# RN831X_RN861X_MCU register map
File version: v0.0.1
CPU: RN831X_RN861X_MCU r1p0, little endian, MPU, no FPU
Registers are 32-bit, read-write, reset 0x0 unless marked. A register's access mark holds for its fields unless they carry their own. Offsets are from the block's base; [hi:lo] are bit positions; {n}, {i} and the like mark numbered series; 'fields as' and 'values as' point back to an identical list.

## GIC_CORE0 — GIC Module core0
Base 0x3001C000
Same registers: GIC_CORE1 0xB001C000
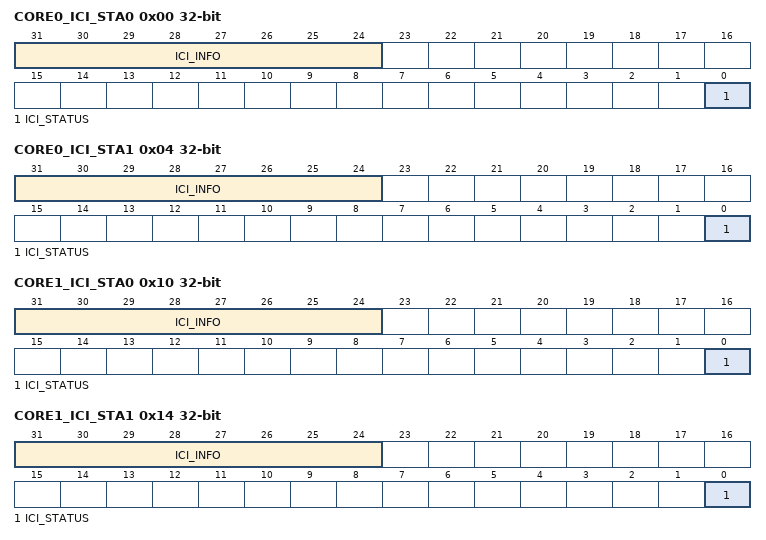
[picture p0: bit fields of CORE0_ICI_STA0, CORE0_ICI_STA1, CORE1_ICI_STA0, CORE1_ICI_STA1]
0x00 CORE0_ICI_STA0 access per field — CORE0 Inter-Core Interrupt Status Register 0
  [31:24] ICI_INFO ro — 8-bit message received by CORE0 when receiving inter-core interrupt from CORE0
  [0] ICI_STATUS rw write-1-clears — Inter-core interrupt status bit sent from CORE0 to CORE0
0x04 CORE0_ICI_STA1 access per field — CORE0 Inter-Core Interrupt Status Register 1
  [31:24] ICI_INFO ro — 8-bit message received by CORE0 when receiving inter-core interrupt from CORE1
  [0] ICI_STATUS rw write-1-clears — Inter-core interrupt status bit sent from CORE1 to CORE0
0x10 CORE1_ICI_STA0 access per field — CORE1 Inter-Core Interrupt Status Register 0
  [31:24] ICI_INFO ro — 8-bit message received by CORE0 when receiving inter-core interrupt from CORE1
  [0] ICI_STATUS rw write-1-clears — Inter-core interrupt status bit sent from CORE0 to CORE0
0x14 CORE1_ICI_STA1 access per field — CORE1 Inter-Core Interrupt Status Register 1
  fields as CORE0_ICI_STA0
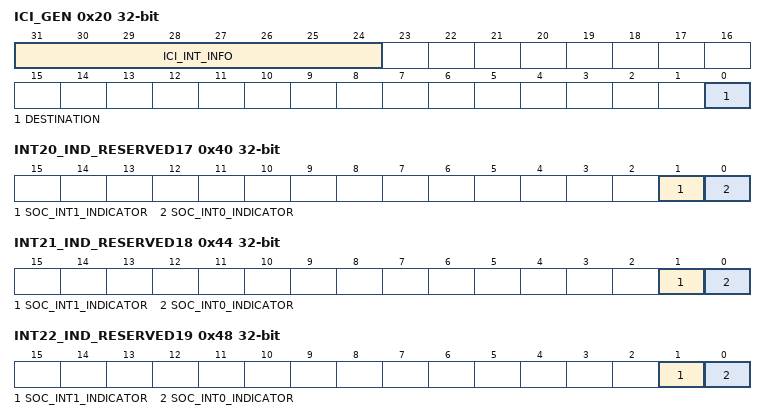
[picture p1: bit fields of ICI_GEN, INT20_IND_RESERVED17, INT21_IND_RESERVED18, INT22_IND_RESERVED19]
0x20 ICI_GEN wo — Inter-Core Interrupt Control Register
  [31:24] ICI_INT_INFO — 8-bit message sent to the core receiving inter-core interrupt
  [0] DESTINATION — Write the CORE_id of the core that will receive the inter-core interrupt
0x24 CORE_IND_LOCK access not given — Core Interrupt Lock Register
  [31:0] CORE_IND_LOCK — Core interrupt lock configuration
0x28 CORE_NUM access not given — Core Number Register
  [31:0] CORE_NUM — Number of cores in the system
0x2C HART_NUM access not given — HART Number Register
  [31:0] HART_NUM — Number of HART buses in the system
0x30 SOC_IRQ_NUM access not given — Interrupt Number Register
  [31:0] SOC_IRQ_NUM — Number of external interrupts in the system
0x40 INT20_IND_RESERVED17 — SOC Interrupt20 Indicator Register
  [1] SOC_INT1_INDICATOR — Whether external interrupt n is assigned to CORE1
  [0] SOC_INT0_INDICATOR — Whether external interrupt n is assigned to CORE0
0x44 INT21_IND_RESERVED18 — SOC Interrupt21 Indicator Register
  fields as INT20_IND_RESERVED17
0x48 INT22_IND_RESERVED19 — SOC Interrupt22 Indicator Register
  fields as INT20_IND_RESERVED17
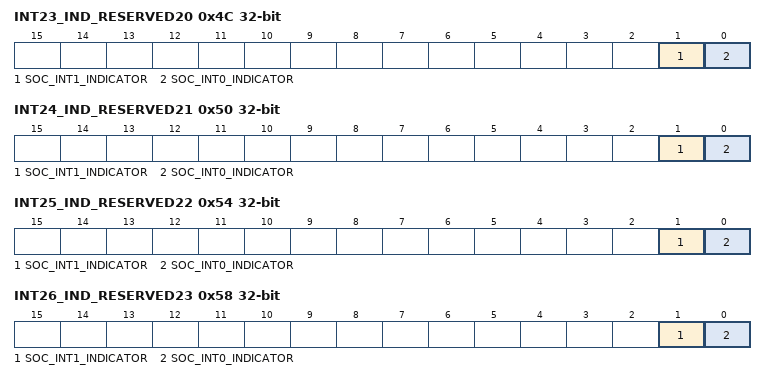
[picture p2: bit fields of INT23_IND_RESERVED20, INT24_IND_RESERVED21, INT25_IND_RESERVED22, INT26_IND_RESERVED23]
0x4C INT23_IND_RESERVED20 — SOC Interrupt23 Indicator Register
  fields as INT20_IND_RESERVED17
0x50 INT24_IND_RESERVED21 — SOC Interrupt24 Indicator Register
  fields as INT20_IND_RESERVED17
0x54 INT25_IND_RESERVED22 — SOC Interrupt25 Indicator Register
  fields as INT20_IND_RESERVED17
0x58 INT26_IND_RESERVED23 — SOC Interrupt26 Indicator Register
  fields as INT20_IND_RESERVED17
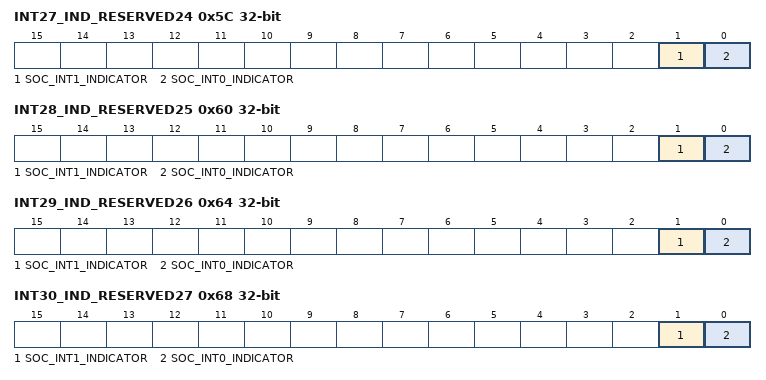
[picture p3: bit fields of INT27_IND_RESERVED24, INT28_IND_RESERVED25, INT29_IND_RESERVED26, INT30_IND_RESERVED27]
0x5C INT27_IND_RESERVED24 — SOC Interrupt27 Indicator Register
  fields as INT20_IND_RESERVED17
0x60 INT28_IND_RESERVED25 — SOC Interrupt28 Indicator Register
  fields as INT20_IND_RESERVED17
0x64 INT29_IND_RESERVED26 — SOC Interrupt29 Indicator Register
  fields as INT20_IND_RESERVED17
0x68 INT30_IND_RESERVED27 — SOC Interrupt30 Indicator Register
  fields as INT20_IND_RESERVED17
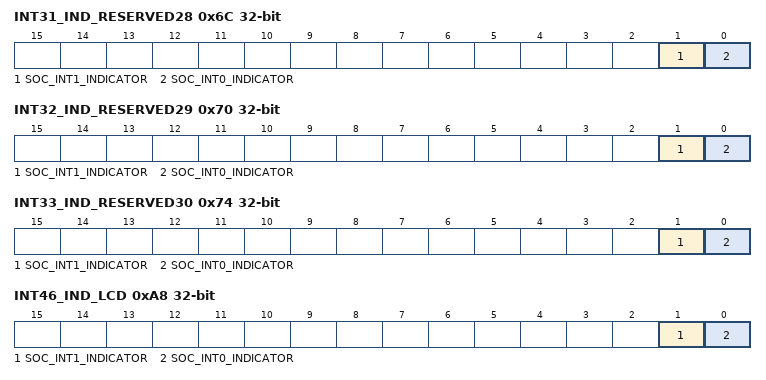
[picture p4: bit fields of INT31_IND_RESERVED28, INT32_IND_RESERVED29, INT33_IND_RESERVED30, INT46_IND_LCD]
0x6C INT31_IND_RESERVED28 — SOC Interrupt31 Indicator Register
  fields as INT20_IND_RESERVED17
0x70 INT32_IND_RESERVED29 — SOC Interrupt32 Indicator Register
  fields as INT20_IND_RESERVED17
0x74 INT33_IND_RESERVED30 — SOC Interrupt33 Indicator Register
  fields as INT20_IND_RESERVED17
0x78 INT34_IND_RESERVED31 access not given — SOC Interrupt34 Indicator Register
  [0] SOC_INT_INDICATOR — Whether external interrupt n is assigned to CORE0/CORE1
0x7C INT35_IND_RESERVED32 access not given — SOC Interrupt35 Indicator Register
  fields as INT34_IND_RESERVED31
0x80 INT36_IND_RESERVED33 access not given — SOC Interrupt36 Indicator Register
  fields as INT34_IND_RESERVED31
0x84 INT37_IND_RESERVED34 access not given — SOC Interrupt37 Indicator Register
  fields as INT34_IND_RESERVED31
0x88 INT38_IND_RESERVED35 access not given — SOC Interrupt38 Indicator Register
  fields as INT34_IND_RESERVED31
0x8C INT39_IND_RESERVED36 access not given — SOC Interrupt39 Indicator Register
  fields as INT34_IND_RESERVED31
0x90 INT40_IND_RESERVED37 access not given — SOC Interrupt40 Indicator Register
  fields as INT34_IND_RESERVED31
0x94 INT41_IND_RESERVED38 access not given — SOC Interrupt41 Indicator Register
  fields as INT34_IND_RESERVED31
0x98 INT42_IND_RESERVED39 access not given — SOC Interrupt42 Indicator Register
  fields as INT34_IND_RESERVED31
0x9C INT43_IND_RESERVED40 access not given — SOC Interrupt43 Indicator Register
  fields as INT34_IND_RESERVED31
0xA0 INT44_IND_RESERVED41 access not given — SOC Interrupt44 Indicator Register
  fields as INT34_IND_RESERVED31
0xA4 INT45_IND_RESERVED42 access not given — SOC Interrupt45 Indicator Register
  fields as INT34_IND_RESERVED31
0xA8 INT46_IND_LCD — SOC Interrupt46 Indicator Register
  fields as INT20_IND_RESERVED17
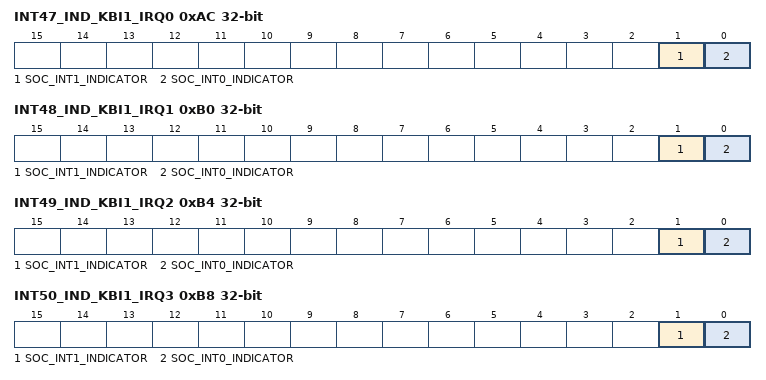
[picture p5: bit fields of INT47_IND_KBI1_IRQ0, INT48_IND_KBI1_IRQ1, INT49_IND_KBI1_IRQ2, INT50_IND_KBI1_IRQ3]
0xAC INT47_IND_KBI1_IRQ0 — SOC Interrupt47 Indicator Register
  fields as INT20_IND_RESERVED17
0xB0 INT48_IND_KBI1_IRQ1 — SOC Interrupt48 Indicator Register
  fields as INT20_IND_RESERVED17
0xB4 INT49_IND_KBI1_IRQ2 — SOC Interrupt49 Indicator Register
  fields as INT20_IND_RESERVED17
0xB8 INT50_IND_KBI1_IRQ3 — SOC Interrupt50 Indicator Register
  fields as INT20_IND_RESERVED17
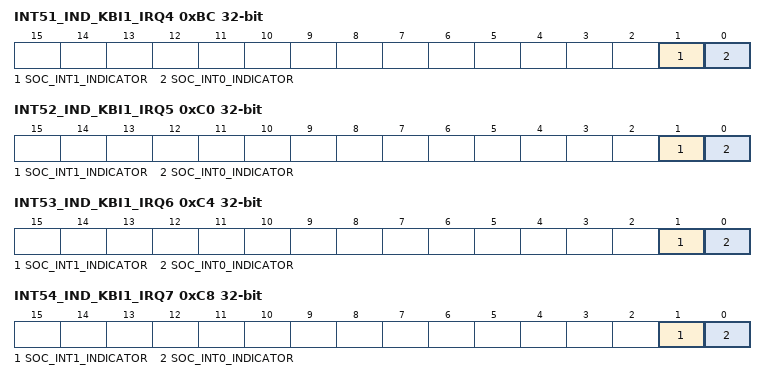
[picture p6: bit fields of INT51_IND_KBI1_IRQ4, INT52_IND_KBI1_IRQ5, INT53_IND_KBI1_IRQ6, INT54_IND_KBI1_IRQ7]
0xBC INT51_IND_KBI1_IRQ4 — SOC Interrupt51 Indicator Register
  fields as INT20_IND_RESERVED17
0xC0 INT52_IND_KBI1_IRQ5 — SOC Interrupt52 Indicator Register
  fields as INT20_IND_RESERVED17
0xC4 INT53_IND_KBI1_IRQ6 — SOC Interrupt53 Indicator Register
  fields as INT20_IND_RESERVED17
0xC8 INT54_IND_KBI1_IRQ7 — SOC Interrupt54 Indicator Register
  fields as INT20_IND_RESERVED17
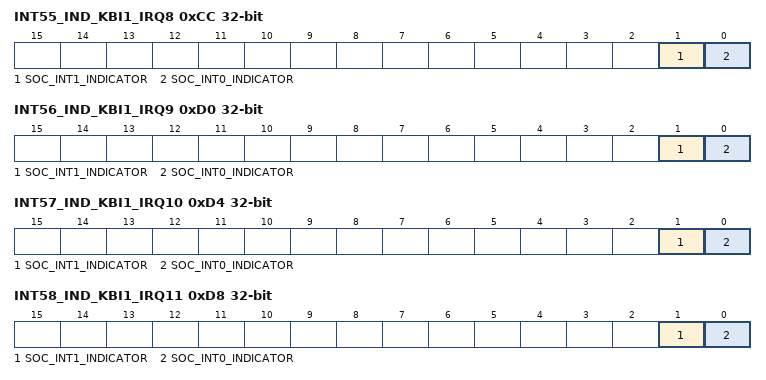
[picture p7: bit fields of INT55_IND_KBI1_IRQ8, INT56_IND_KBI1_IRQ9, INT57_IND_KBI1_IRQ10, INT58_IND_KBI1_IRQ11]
0xCC INT55_IND_KBI1_IRQ8 — SOC Interrupt55 Indicator Register
  fields as INT20_IND_RESERVED17
0xD0 INT56_IND_KBI1_IRQ9 — SOC Interrupt56 Indicator Register
  fields as INT20_IND_RESERVED17
0xD4 INT57_IND_KBI1_IRQ10 — SOC Interrupt57 Indicator Register
  fields as INT20_IND_RESERVED17
0xD8 INT58_IND_KBI1_IRQ11 — SOC Interrupt58 Indicator Register
  fields as INT20_IND_RESERVED17
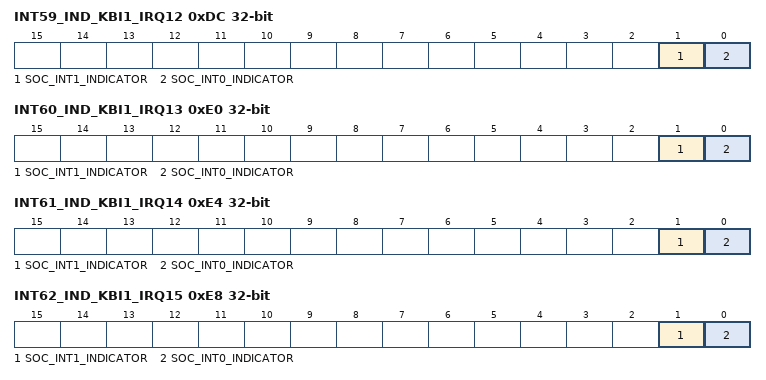
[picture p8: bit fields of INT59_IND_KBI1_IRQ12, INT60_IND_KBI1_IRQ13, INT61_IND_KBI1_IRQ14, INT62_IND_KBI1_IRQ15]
0xDC INT59_IND_KBI1_IRQ12 — SOC Interrupt59 Indicator Register
  fields as INT20_IND_RESERVED17
0xE0 INT60_IND_KBI1_IRQ13 — SOC Interrupt60 Indicator Register
  fields as INT20_IND_RESERVED17
0xE4 INT61_IND_KBI1_IRQ14 — SOC Interrupt61 Indicator Register
  fields as INT20_IND_RESERVED17
0xE8 INT62_IND_KBI1_IRQ15 — SOC Interrupt62 Indicator Register
  fields as INT20_IND_RESERVED17
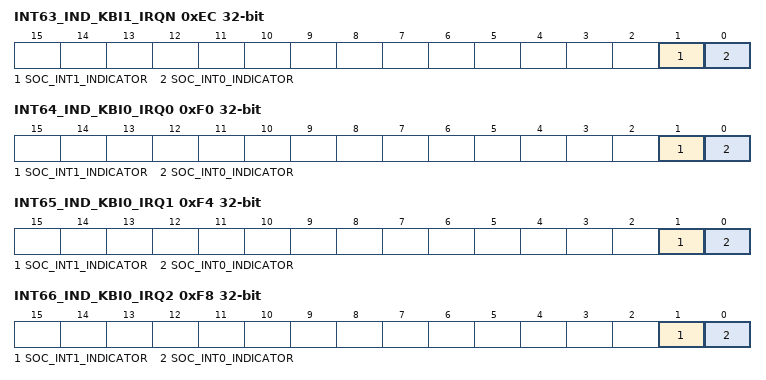
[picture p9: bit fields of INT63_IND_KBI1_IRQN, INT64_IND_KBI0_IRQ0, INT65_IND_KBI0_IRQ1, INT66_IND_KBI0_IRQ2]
0xEC INT63_IND_KBI1_IRQN — SOC Interrupt63 Indicator Register
  fields as INT20_IND_RESERVED17
0xF0 INT64_IND_KBI0_IRQ0 — SOC Interrupt64 Indicator Register
  fields as INT20_IND_RESERVED17
0xF4 INT65_IND_KBI0_IRQ1 — SOC Interrupt65 Indicator Register
  fields as INT20_IND_RESERVED17
0xF8 INT66_IND_KBI0_IRQ2 — SOC Interrupt66 Indicator Register
  fields as INT20_IND_RESERVED17
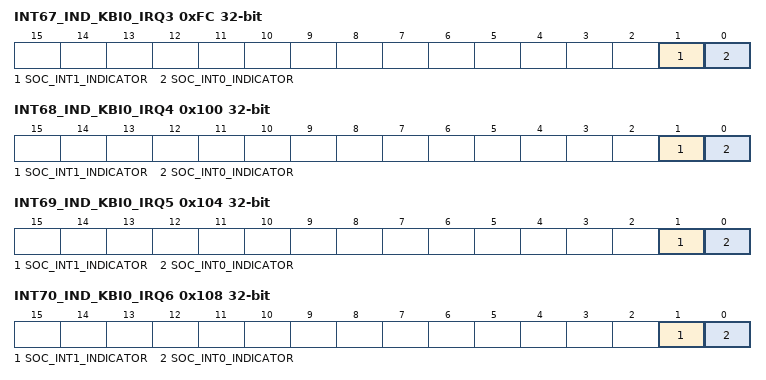
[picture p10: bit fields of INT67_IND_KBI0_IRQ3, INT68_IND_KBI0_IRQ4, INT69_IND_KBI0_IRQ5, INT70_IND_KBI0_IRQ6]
0xFC INT67_IND_KBI0_IRQ3 — SOC Interrupt67 Indicator Register
  fields as INT20_IND_RESERVED17
0x100 INT68_IND_KBI0_IRQ4 — SOC Interrupt68 Indicator Register
  fields as INT20_IND_RESERVED17
0x104 INT69_IND_KBI0_IRQ5 — SOC Interrupt69 Indicator Register
  fields as INT20_IND_RESERVED17
0x108 INT70_IND_KBI0_IRQ6 — SOC Interrupt70 Indicator Register
  fields as INT20_IND_RESERVED17
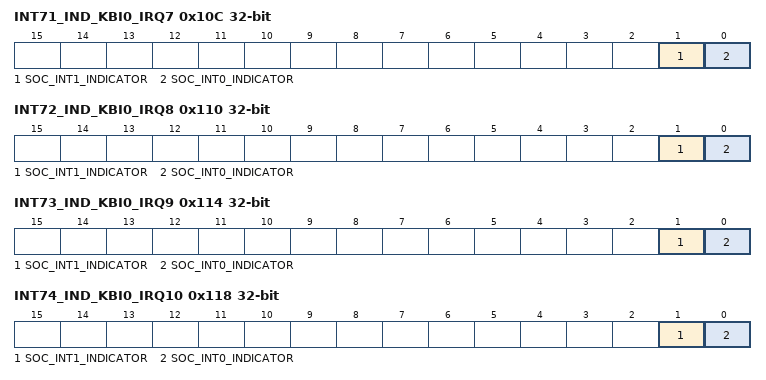
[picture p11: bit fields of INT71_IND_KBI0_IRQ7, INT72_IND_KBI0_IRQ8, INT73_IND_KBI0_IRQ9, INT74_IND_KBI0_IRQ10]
0x10C INT71_IND_KBI0_IRQ7 — SOC Interrupt71 Indicator Register
  fields as INT20_IND_RESERVED17
0x110 INT72_IND_KBI0_IRQ8 — SOC Interrupt72 Indicator Register
  fields as INT20_IND_RESERVED17
0x114 INT73_IND_KBI0_IRQ9 — SOC Interrupt73 Indicator Register
  fields as INT20_IND_RESERVED17
0x118 INT74_IND_KBI0_IRQ10 — SOC Interrupt74 Indicator Register
  fields as INT20_IND_RESERVED17
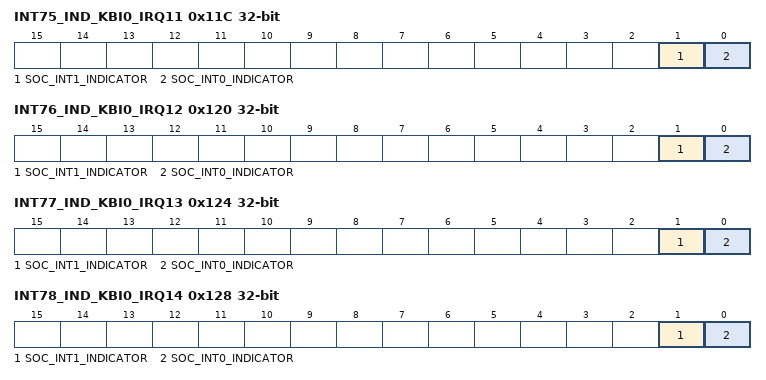
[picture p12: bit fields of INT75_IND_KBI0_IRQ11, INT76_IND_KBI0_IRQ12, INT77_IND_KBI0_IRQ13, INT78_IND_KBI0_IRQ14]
0x11C INT75_IND_KBI0_IRQ11 — SOC Interrupt75 Indicator Register
  fields as INT20_IND_RESERVED17
0x120 INT76_IND_KBI0_IRQ12 — SOC Interrupt76 Indicator Register
  fields as INT20_IND_RESERVED17
0x124 INT77_IND_KBI0_IRQ13 — SOC Interrupt77 Indicator Register
  fields as INT20_IND_RESERVED17
0x128 INT78_IND_KBI0_IRQ14 — SOC Interrupt78 Indicator Register
  fields as INT20_IND_RESERVED17
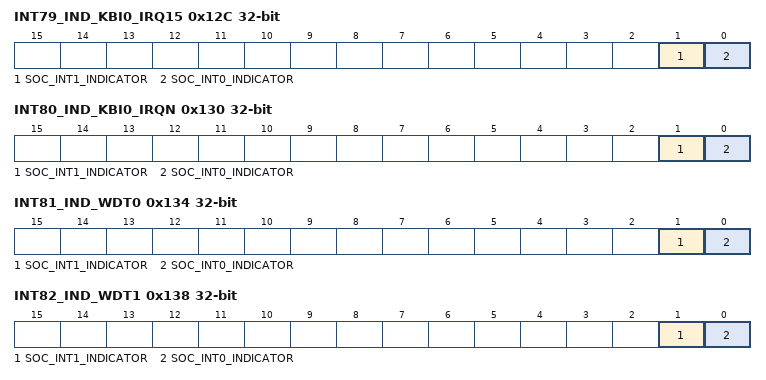
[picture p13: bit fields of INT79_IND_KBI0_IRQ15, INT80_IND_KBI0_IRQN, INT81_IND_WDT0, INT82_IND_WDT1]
0x12C INT79_IND_KBI0_IRQ15 — SOC Interrupt79 Indicator Register
  fields as INT20_IND_RESERVED17
0x130 INT80_IND_KBI0_IRQN — SOC Interrupt80 Indicator Register
  fields as INT20_IND_RESERVED17
0x134 INT81_IND_WDT0 — SOC Interrupt81 Indicator Register
  fields as INT20_IND_RESERVED17
0x138 INT82_IND_WDT1 — SOC Interrupt82 Indicator Register
  fields as INT20_IND_RESERVED17
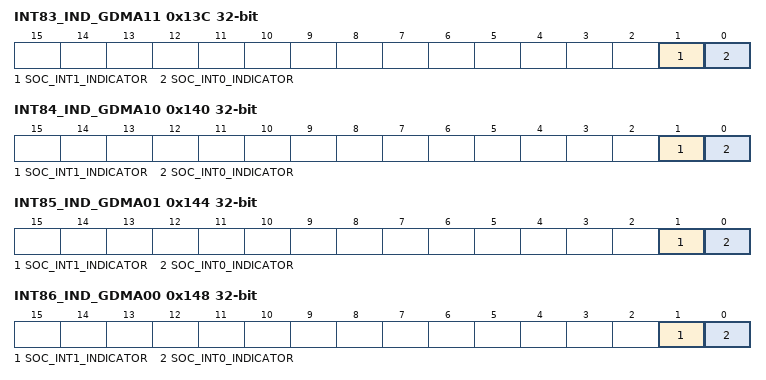
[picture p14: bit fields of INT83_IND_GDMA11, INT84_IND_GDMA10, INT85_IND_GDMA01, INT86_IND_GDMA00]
0x13C INT83_IND_GDMA11 — SOC Interrupt83 Indicator Register
  fields as INT20_IND_RESERVED17
0x140 INT84_IND_GDMA10 — SOC Interrupt84 Indicator Register
  fields as INT20_IND_RESERVED17
0x144 INT85_IND_GDMA01 — SOC Interrupt85 Indicator Register
  fields as INT20_IND_RESERVED17
0x148 INT86_IND_GDMA00 — SOC Interrupt86 Indicator Register
  fields as INT20_IND_RESERVED17
0x150 INT88_IND_SIMPTC0_0 — SOC Interrupt88 Indicator Register
  fields as INT20_IND_RESERVED17
0x154 INT89_IND_SIMPTC0_1 — SOC Interrupt89 Indicator Register
  fields as INT20_IND_RESERVED17
0x158 INT90_IND_SIMPTC0_2 — SOC Interrupt90 Indicator Register
  fields as INT20_IND_RESERVED17
0x15C INT91_IND_SIMPTC0_3 — SOC Interrupt91 Indicator Register
  fields as INT20_IND_RESERVED17
0x160 INT92_IND_SIMPTC1_0 — SOC Interrupt92 Indicator Register
  fields as INT20_IND_RESERVED17
0x164 INT93_IND_SIMPTC1_1 — SOC Interrupt93 Indicator Register
  fields as INT20_IND_RESERVED17
0x168 INT94_IND_SIMPTC1_2 — SOC Interrupt94 Indicator Register
  fields as INT20_IND_RESERVED17
0x16C INT95_IND_SIMPTC1_3 — SOC Interrupt95 Indicator Register
  fields as INT20_IND_RESERVED17
0x170 INT96_IND_SIMPTC2_0 — SOC Interrupt96 Indicator Register
  fields as INT20_IND_RESERVED17
0x174 INT97_IND_SIMPTC2_1 — SOC Interrupt97 Indicator Register
  fields as INT20_IND_RESERVED17
0x178 INT98_IND_SIMPTC2_2 — SOC Interrupt98 Indicator Register
  fields as INT20_IND_RESERVED17
0x17C INT99_IND_SIMPTC2_3 — SOC Interrupt99 Indicator Register
  fields as INT20_IND_RESERVED17
0x180 INT100_IND_SIMPTC3_0 — SOC Interrupt100 Indicator Register
  fields as INT20_IND_RESERVED17
0x184 INT101_IND_SIMPTC3_1 — SOC Interrupt101 Indicator Register
  fields as INT20_IND_RESERVED17
0x188 INT102_IND_SIMPTC3_2 — SOC Interrupt102 Indicator Register
  fields as INT20_IND_RESERVED17
0x18C INT103_IND_SIMPTC3_3 — SOC Interrupt103 Indicator Register
  fields as INT20_IND_RESERVED17
0x190 INT104_IND_TC0 — SOC Interrupt104 Indicator Register
  fields as INT20_IND_RESERVED17
0x194 INT105_IND_TC1 — SOC Interrupt105 Indicator Register
  fields as INT20_IND_RESERVED17
0x198 INT106_IND_ISO78160 — SOC Interrupt106 Indicator Register
  fields as INT20_IND_RESERVED17
0x19C INT107_IND_ISO78161 — SOC Interrupt107 Indicator Register
  fields as INT20_IND_RESERVED17
0x1A0 INT108_IND_I2C0 — SOC Interrupt108 Indicator Register
  fields as INT20_IND_RESERVED17
0x1A4 INT109_IND_I2C1 — SOC Interrupt109 Indicator Register
  fields as INT20_IND_RESERVED17
0x1A8 INT110_IND_LPUART — SOC Interrupt110 Indicator Register
  fields as INT20_IND_RESERVED17
0x1AC INT111_IND_LSRX — SOC Interrupt111 Indicator Register
  fields as INT20_IND_RESERVED17
{0x1B0+4i} INT{i+112}_IND_UART{i} (i=0..7) — SOC Interrupt{i+112} Indicator Register
  fields as INT20_IND_RESERVED17
0x1D0 INT120_IND_USART0 — SOC Interrupt120 Indicator Register
  fields as INT20_IND_RESERVED17
0x1D4 INT121_IND_USART1 — SOC Interrupt121 Indicator Register
  fields as INT20_IND_RESERVED17
{0x1DC+4i} INT{i+123}_IND_SPI{i} (i=0..3) — SOC Interrupt{i+123} Indicator Register
  fields as INT20_IND_RESERVED17
0x1EC INT127_IND_QSPI0 — SOC Interrupt127 Indicator Register
  fields as INT20_IND_RESERVED17
0x1F0 INT128_IND_QSPI1 — SOC Interrupt128 Indicator Register
  fields as INT20_IND_RESERVED17
0x1F4 INT129_IND_DSP — SOC Interrupt129 Indicator Register
  fields as INT20_IND_RESERVED17
0x1F8 INT130_IND_M2M — SOC Interrupt130 Indicator Register
  fields as INT20_IND_RESERVED17
0x1FC INT131_IND_AES — SOC Interrupt131 Indicator Register
  fields as INT20_IND_RESERVED17
0x200 INT132_IND_SEA — SOC Interrupt132 Indicator Register
  fields as INT20_IND_RESERVED17
0x204 INT133_IND_KEYSTORE — SOC Interrupt133 Indicator Register
  fields as INT20_IND_RESERVED17
0x208 INT134_IND_DAC — SOC Interrupt134 Indicator Register
  fields as INT20_IND_RESERVED17
0x20C INT135_IND_ADC0 — SOC Interrupt135 Indicator Register
  fields as INT20_IND_RESERVED17
0x210 INT136_IND_D2F — SOC Interrupt136 Indicator Register
  fields as INT20_IND_RESERVED17
0x214 INT137_IND_RTC — SOC Interrupt137 Indicator Register
  fields as INT20_IND_RESERVED17
0x218 INT138_IND_VBAT — SOC Interrupt138 Indicator Register
  fields as INT20_IND_RESERVED17
0x21C INT139_IND_CMPLVD — SOC Interrupt139 Indicator Register
  fields as INT20_IND_RESERVED17
0x220 INT140_IND_LCSS — SOC Interrupt140 Indicator Register
  fields as INT20_IND_RESERVED17
0x224 INT141_IND_SCU — SOC Interrupt141 Indicator Register
  fields as INT20_IND_RESERVED17
0x228 INT142_IND_CORE1_RST — SOC Interrupt142 Indicator Register
  fields as INT20_IND_RESERVED17
0x22C INT143_IND_CORE1_SYSREG — SOC Interrupt143 Indicator Register
  fields as INT20_IND_RESERVED17
0x230 INT144_IND_CORE0_SYSREG — SOC Interrupt144 Indicator Register
  fields as INT20_IND_RESERVED17
0x234 INT145_IND_MAILBOXINTER — SOC Interrupt145 Indicator Register
  fields as INT20_IND_RESERVED17
0x238 INT146_IND_MAILBOXHOST0 — SOC Interrupt146 Indicator Register
  fields as INT20_IND_RESERVED17
